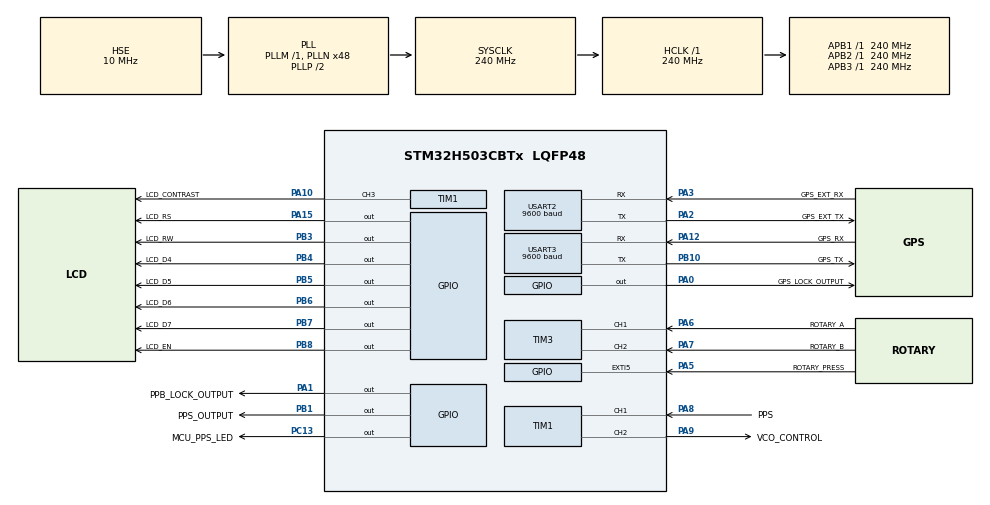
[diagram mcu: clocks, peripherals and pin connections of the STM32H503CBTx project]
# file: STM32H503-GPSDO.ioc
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BOOTPATH.BootPathName=LEGACY
BOOTPATH.UserSelectedBootPath=LEGACY
FLASH.advanced_settings=false
GPDMA1.IPHANDLE_GPDMACH3-SIMPLEREQUEST_GPDMACH3=__NULL
GPDMA1.IPHANDLE_GPDMACH6-SIMPLEREQUEST_GPDMACH6=__NULL
GPDMA1.REQUEST_GPDMACH3=GPDMA1_REQUEST_USART3_RX
GPDMA1.REQUEST_GPDMACH6=GPDMA1_REQUEST_USART2_RX
Mcu.Family=STM32H5
Mcu.Name=STM32H503CBTx
Mcu.Package=LQFP48
NVIC.EXTI5_IRQn=true\:0\:0\:false\:false\:true\:true\:true\:true
NVIC.GPDMA1_Channel3_IRQn=true\:0\:0\:false\:false\:true\:false\:true\:true
NVIC.GPDMA1_Channel6_IRQn=true\:0\:0\:false\:false\:true\:false\:true\:true
NVIC.ICACHE_IRQn=true\:0\:0\:false\:false\:true\:true\:true\:true
NVIC.PriorityGroup=NVIC_PRIORITYGROUP_4
NVIC.TIM1_CC_IRQn=true\:0\:0\:false\:false\:true\:true\:true\:true
NVIC.TIM1_UP_IRQn=true\:0\:0\:false\:false\:true\:true\:true\:true
NVIC.TIM2_IRQn=true\:0\:0\:false\:false\:true\:true\:true\:true
NVIC.USART2_IRQn=true\:0\:0\:false\:false\:true\:true\:true\:true
NVIC.USART3_IRQn=true\:0\:0\:false\:false\:true\:true\:true\:true
PA0.GPIO_Label=GPS_LOCK_OUTPUT
PA0.GPIO_PuPd=GPIO_NOPULL
PA0.Signal=GPIO_Output
PA1.GPIO_Label=PPB_LOCK_OUTPUT
PA1.Signal=GPIO_Output
PA10.GPIO_Label=LCD_CONTRAST
PA10.Signal=S_TIM1_CH3
PA12.GPIO_Label=GPS_RX
PA12.GPIO_PuPd=GPIO_PULLUP
PA12.Mode=Asynchronous
PA12.Signal=USART3_RX
PA13(JTMS/SWDIO).Mode=Serial_Wire
PA13(JTMS/SWDIO).Signal=DEBUG_JTMS-SWDIO
PA14(JTCK/SWCLK).Mode=Serial_Wire
PA14(JTCK/SWCLK).Signal=DEBUG_JTCK-SWCLK
PA15(JTDI).GPIO_Label=LCD_RS
PA15(JTDI).Signal=GPIO_Output
PA2.GPIO_Label=GPS_EXT_TX
PA2.GPIO_Speed=GPIO_SPEED_FREQ_HIGH
PA2.Mode=Asynchronous
PA2.Signal=USART2_TX
PA3.GPIO_Label=GPS_EXT_RX
PA3.GPIO_PuPd=GPIO_PULLUP
PA3.GPIO_Speed=GPIO_SPEED_FREQ_LOW
PA3.Mode=Asynchronous
PA3.Signal=USART2_RX
PA5.GPIO_Label=ROTARY_PRESS
PA5.GPIO_PuPd=GPIO_PULLUP
PA5.Signal=GPXTI5
PA6.GPIO_Label=ROTARY_A
PA6.GPIO_ModeDefaultPP=GPIO_MODE_AF_PP
PA6.GPIO_PuPd=GPIO_PULLUP
PA6.Signal=S_TIM3_CH1
PA7.GPIO_Label=ROTARY_B
PA7.GPIO_PuPd=GPIO_PULLUP
PA7.Signal=S_TIM3_CH2
PA8.GPIO_Label=PPS
PA8.GPIO_PuPd=GPIO_PULLDOWN
PA8.Signal=S_TIM1_CH1
PA9.GPIO_Label=VCO_CONTROL
PA9.Signal=S_TIM1_CH2
PB1.GPIO_Label=PPS_OUTPUT
PB1.Signal=GPIO_Output
PB10.GPIO_Label=GPS_TX
PB10.GPIO_PuPd=GPIO_NOPULL
PB10.GPIO_Speed=GPIO_SPEED_FREQ_HIGH
PB10.Mode=Asynchronous
PB10.Signal=USART3_TX
PB3(JTDO/TRACESWO).GPIO_Label=LCD_RW
PB3(JTDO/TRACESWO).Signal=GPIO_Output
PB4(NJTRST).GPIO_Label=LCD_D4
PB4(NJTRST).Signal=GPIO_Output
PB5.GPIO_Label=LCD_D5
PB5.Signal=GPIO_Output
PB6.GPIO_Label=LCD_D6
PB6.Signal=GPIO_Output
PB7.GPIO_Label=LCD_D7
PB7.Signal=GPIO_Output
PB8.GPIO_Label=LCD_EN
PB8.Signal=GPIO_Output
PC13.GPIO_Label=MCU_PPS_LED
PC13.GPIO_PuPd=GPIO_NOPULL
PC13.GPIO_Speed=GPIO_SPEED_FREQ_LOW
PC13.PinState=GPIO_PIN_SET
PC13.Signal=GPIO_Output
PC14-OSC32_IN(OSC32_IN).Mode=LSE-External-Oscillator
PC14-OSC32_IN(OSC32_IN).Signal=RCC_OSC32_IN
PC15-OSC32_OUT(OSC32_OUT).Mode=LSE-External-Oscillator
PC15-OSC32_OUT(OSC32_OUT).Signal=RCC_OSC32_OUT
PH0-OSC_IN(PH0).Mode=HSE-External-Clock-Source
PH0-OSC_IN(PH0).Signal=RCC_OSC_IN
ProjectManager.HeapSize=0x200
ProjectManager.StackSize=0x400
ProjectManager.TargetToolchain=CMake
RAMCFG.Instance-BKPRAM_Activate=RAMCFG_BKPRAM
RAMCFG.Instance-RAMCFG1_Activate=RAMCFG_SRAM1
RAMCFG.Instance-RAMCFG2_Activate=RAMCFG_SRAM2
RCC.ADCFreq_Value=240000000
RCC.AHBFreq_Value=240000000
RCC.APB1Freq_Value=240000000
RCC.APB1TimFreq_Value=240000000
RCC.APB2Freq_Value=240000000
RCC.APB2TimFreq_Value=240000000
RCC.APB3Freq_Value=240000000
RCC.CSI_VALUE=4000000
RCC.CortexFreq_Value=240000000
RCC.EPOD_VALUE=10000000
RCC.HCLKFreq_Value=240000000
RCC.HSE_Timout=1500
RCC.HSE_VALUE=10000000
RCC.HSI48_VALUE=48000000
RCC.HSICalibrationValue=16
RCC.HSIDiv=RCC_HSI_DIV1
RCC.HSI_VALUE=64000000
RCC.LSIRC_VALUE=32000
RCC.PLL2FRACN=0
RCC.PLL2N=32
RCC.PLLN=48
RCC.PLLSourceVirtual=RCC_PLL1_SOURCE_HSE
RCC.SYSCLKFreq_VALUE=240000000
RCC.SYSCLKSource=RCC_SYSCLKSOURCE_PLLCLK
RCC.USART2CLockSelection=RCC_USART2CLKSOURCE_HSI
RCC.USART3CLockSelection=RCC_USART3CLKSOURCE_PLL2Q
RCC.USBFreq_Value=48000000
RCC.VCOOutputFreq_Value=480000000
SH.S_TIM1_CH1.0=TIM1_CH1,Input_Capture1_from_TI1
SH.S_TIM1_CH2.0=TIM1_CH2,PWM Generation2 CH2
SH.S_TIM1_CH3.0=TIM1_CH3,PWM Generation3 CH3
SH.S_TIM3_CH1.0=TIM3_CH1,Encoder_Interface
SH.S_TIM3_CH2.0=TIM3_CH2,Encoder_Interface
TIM1.Channel-Input_Capture1_from_TI1=TIM_CHANNEL_1
TIM1.Channel-PWM\ Generation2\ CH2=TIM_CHANNEL_2
TIM1.Channel-PWM\ Generation3\ CH3=TIM_CHANNEL_3
TIM1.OCFastMode_PWM-PWM\ Generation2\ CH2=TIM_OCFAST_ENABLE
TIM2.PeriodNoDither=9999
TIM2.Prescaler=6999
TIM3.IC1Filter=15
TIM3.IC2Filter=15
USART2.BaudRate=9600
USART2.VirtualMode-Asynchronous=VM_ASYNC
USART3.BaudRate=9600
USART3.VirtualMode-Asynchronous=VM_ASYNC
VP_BOOTPATH_VS_BOOTPATH.Mode=BP_Activate
VP_CORTEX_M33_NS_VS_Hclk.Mode=Hclk_Mode
VP_FLASH_SIG_Activate_FlashIP.Mode=Activate_FlashIP
VP_GPDMA1_VS_GPDMACH3.Mode=SIMPLEREQUEST_GPDMACH3
VP_GPDMA1_VS_GPDMACH6.Mode=SIMPLEREQUEST_GPDMACH6
VP_ICACHE_VS_ICACHE.Mode=DefaultMode
VP_MEMORYMAP_VS_MEMORYMAP.Mode=CurAppReg
VP_PWR_VS_LPOM.Mode=PowerOptimisation
VP_PWR_VS_SECSignals.Mode=Security/Privilege
VP_RAMCFG_VS_BKPRAM.Mode=BKPRAM_Activate
VP_RAMCFG_VS_RAMCFG1.Mode=RAMCFG1_Activate
VP_RAMCFG_VS_RAMCFG2.Mode=RAMCFG2_Activate
VP_TIM1_VS_ClockSourceINT.Mode=Internal
VP_TIM2_VS_ClockSourceINT.Mode=Internal
board=custom

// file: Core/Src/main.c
/* USER CODE BEGIN Header */
/**
  ******************************************************************************
  * @file           : main.c
  * @brief          : Main program body
  ******************************************************************************
  * @attention
  *
  * Copyright (c) 2025 STMicroelectronics.
  * All rights reserved.
  *
  * This software is licensed under terms that can be found in the LICENSE file
  * in the root directory of this software component.
  * If no LICENSE file comes with this software, it is provided AS-IS.
  *
  ******************************************************************************
  */
/* USER CODE END Header */
#include "main.h"
#include "flash.h"
#include "gpdma.h"
#include "icache.h"
#include "memorymap.h"
#include "ramcfg.h"
#include "tim.h"
#include "usart.h"
#include "gpio.h"

/* USER CODE BEGIN PD */
void gpsdo();
/* USER CODE END PD */

void SystemClock_Config(void);

int main(void)
{

  /* MCU Configuration--------------------------------------------------------*/

  /* Reset of all peripherals, Initializes the Flash interface and the Systick. */
  HAL_Init();

  /* Configure the system clock */
  SystemClock_Config();

  /* Initialize all configured peripherals */
  MX_GPIO_Init();
  MX_GPDMA1_Init();
  MX_TIM1_Init();
  MX_TIM2_Init();
  MX_TIM3_Init();
  MX_USART3_UART_Init();
  MX_USART2_UART_Init();
  MX_ICACHE_Init();
  MX_FLASH_Init();
  MX_RAMCFG_Init();
  /* USER CODE BEGIN 2 */
  gpsdo();
  /* USER CODE END 2 */

  /* Infinite loop */
  while (1)
  {

  }
}

void SystemClock_Config(void)
{
  RCC_OscInitTypeDef RCC_OscInitStruct = {0};
  RCC_ClkInitTypeDef RCC_ClkInitStruct = {0};

  /** Configure the main internal regulator output voltage
  */
  __HAL_PWR_VOLTAGESCALING_CONFIG(PWR_REGULATOR_VOLTAGE_SCALE0);

  while(!__HAL_PWR_GET_FLAG(PWR_FLAG_VOSRDY)) {}

  /** Initializes the RCC Oscillators according to the specified parameters
  * in the RCC_OscInitTypeDef structure.
  */
  RCC_OscInitStruct.OscillatorType = RCC_OSCILLATORTYPE_HSE|RCC_OSCILLATORTYPE_CSI;
  RCC_OscInitStruct.HSEState = RCC_HSE_BYPASS;
  RCC_OscInitStruct.CSIState = RCC_CSI_ON;
  RCC_OscInitStruct.CSICalibrationValue = RCC_CSICALIBRATION_DEFAULT;
  RCC_OscInitStruct.PLL.PLLState = RCC_PLL_ON;
  RCC_OscInitStruct.PLL.PLLSource = RCC_PLL1_SOURCE_HSE;
  RCC_OscInitStruct.PLL.PLLM = 1;
  RCC_OscInitStruct.PLL.PLLN = 48;
  RCC_OscInitStruct.PLL.PLLP = 2;
  RCC_OscInitStruct.PLL.PLLQ = 2;
  RCC_OscInitStruct.PLL.PLLR = 2;
  RCC_OscInitStruct.PLL.PLLRGE = RCC_PLL1_VCIRANGE_3;
  RCC_OscInitStruct.PLL.PLLVCOSEL = RCC_PLL1_VCORANGE_WIDE;
  RCC_OscInitStruct.PLL.PLLFRACN = 0;
  if (HAL_RCC_OscConfig(&RCC_OscInitStruct) != HAL_OK)
  {
    Error_Handler();
  }

  /** Initializes the CPU, AHB and APB buses clocks
  */
  RCC_ClkInitStruct.ClockType = RCC_CLOCKTYPE_HCLK|RCC_CLOCKTYPE_SYSCLK
                              |RCC_CLOCKTYPE_PCLK1|RCC_CLOCKTYPE_PCLK2
                              |RCC_CLOCKTYPE_PCLK3;
  RCC_ClkInitStruct.SYSCLKSource = RCC_SYSCLKSOURCE_PLLCLK;
  RCC_ClkInitStruct.AHBCLKDivider = RCC_SYSCLK_DIV1;
  RCC_ClkInitStruct.APB1CLKDivider = RCC_HCLK_DIV1;
  RCC_ClkInitStruct.APB2CLKDivider = RCC_HCLK_DIV1;
  RCC_ClkInitStruct.APB3CLKDivider = RCC_HCLK_DIV1;

  if (HAL_RCC_ClockConfig(&RCC_ClkInitStruct, FLASH_LATENCY_5) != HAL_OK)
  {
    Error_Handler();
  }

  /** Configure the programming delay
  */
  __HAL_FLASH_SET_PROGRAM_DELAY(FLASH_PROGRAMMING_DELAY_2);
}

void Error_Handler(void)
{
  __disable_irq();
  while (1)
  {
  }
}
